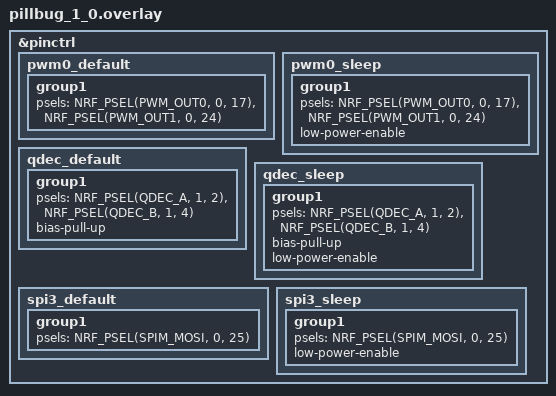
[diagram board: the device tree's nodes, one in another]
/*
 * Copyright (c) 2023 The ZMK Contributors
 *
 * SPDX-License-Identifier: MIT
 */

#include "obe-nrf52.dtsi"

&pinctrl {
    pwm0_default: pwm0_default {
        group1 {
            psels = <NRF_PSEL(PWM_OUT0, 0, 17)>,
                    <NRF_PSEL(PWM_OUT1, 0, 24)>;
        };
    };

    pwm0_sleep: pwm0_sleep {
        group1 {
            psels = <NRF_PSEL(PWM_OUT0, 0, 17)>,
                    <NRF_PSEL(PWM_OUT1, 0, 24)>;
            low-power-enable;
        };
    };

    qdec_default: qdec_default {
        group1 {
            psels = <NRF_PSEL(QDEC_A, 1, 2)>,
                    <NRF_PSEL(QDEC_B, 1, 4)>;
            bias-pull-up;
        };
    };

    qdec_sleep: qdec_sleep {
        group1 {
            psels = <NRF_PSEL(QDEC_A, 1, 2)>,
                    <NRF_PSEL(QDEC_B, 1, 4)>;
            bias-pull-up;
            low-power-enable;
        };
    };

    spi3_default: spi3_default {
        group1 {
            psels = <NRF_PSEL(SPIM_MOSI, 0, 25)>;
        };
    };

    spi3_sleep: spi3_sleep {
        group1 {
            psels = <NRF_PSEL(SPIM_MOSI, 0, 25)>;
            low-power-enable;
        };
    };
};
